# SMS_LITE_FWMGR_0_CBASS_FW_45082000h register map
Vendor: Texas Instruments
Peripheral module from a debugger description file (folder am62L).
Registers are 32-bit, read-write, reset 0x0 unless marked. A register's access mark holds for its fields unless they carry their own. Offsets are as the file gives them; lines under a group give offsets from that group; [hi:lo] are bit positions; {n}, {i} and the like mark numbered series; 'fields as' and 'values as' point back to an identical list; <NAME> marks a mode.

## cbass_fw
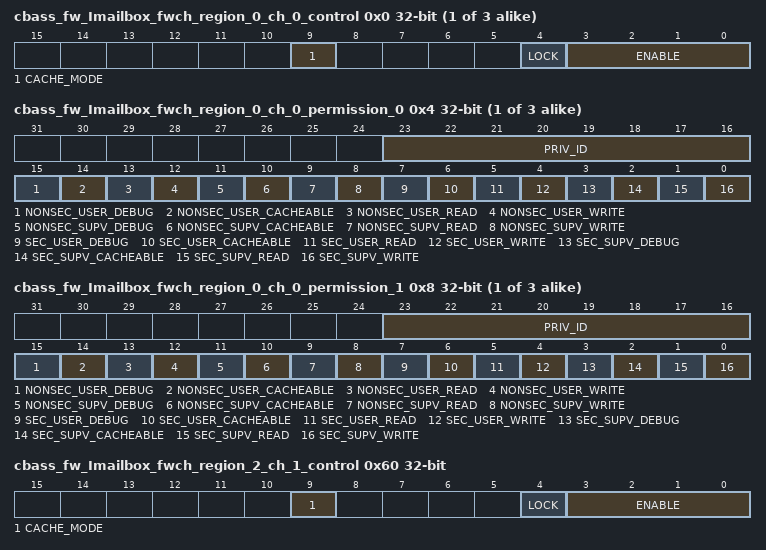
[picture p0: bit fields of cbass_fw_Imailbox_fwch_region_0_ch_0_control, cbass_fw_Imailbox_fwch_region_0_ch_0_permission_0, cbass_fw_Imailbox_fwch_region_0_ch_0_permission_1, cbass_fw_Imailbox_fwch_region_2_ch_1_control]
{0x0+0x20*i} cbass_fw_Imailbox_fwch_region_{i}_ch_0_control access not given (i=0..2) — The FW Region {i} Channel 0 Control Register defines the control fields for the slave Imailbox.cfg region {i} channel 0 firewall.
  [9] CACHE_MODE rw — Cache mode for region. Set to 1 to check cache permissions. Set to 0 to ignore cache permissions. Reset Source: sms_custom_rst_mod_g_rst_n
  [4] LOCK — Lock region. Once set region values cannot be modified. Reset Source: sms_custom_rst_mod_g_rst_n (access R/W1TS)
  [3:0] ENABLE rw — Enable region. A value of 0xA enables, others disable. Reset Source: sms_custom_rst_mod_g_rst_n
{0x4+0x20*i} cbass_fw_Imailbox_fwch_region_{i}_ch_0_permission_0 (i=0..2) — The FW Region {i} Channel 0 Permission 0 Register defines the permissions for the slave Imailbox.cfg region {i} channel 0 firewall.
  [23:16] PRIV_ID — Allowed privid. Reset Source: sms_custom_rst_mod_g_rst_n
  [15] NONSEC_USER_DEBUG — Non-secure user debug allowed. Reset Source: sms_custom_rst_mod_g_rst_n
  [14] NONSEC_USER_CACHEABLE — Non-secure user cacheable allowed. Reset Source: sms_custom_rst_mod_g_rst_n
  [13] NONSEC_USER_READ — Non-secure user read allowed. Reset Source: sms_custom_rst_mod_g_rst_n
  [12] NONSEC_USER_WRITE — Non-secure user write allowed. Reset Source: sms_custom_rst_mod_g_rst_n
  [11] NONSEC_SUPV_DEBUG — Non-secure supervisor debug allowed. Reset Source: sms_custom_rst_mod_g_rst_n
  [10] NONSEC_SUPV_CACHEABLE — Non-secure supervisor cacheable allowed. Reset Source: sms_custom_rst_mod_g_rst_n
  [9] NONSEC_SUPV_READ — Non-secure supervisor read allowed. Reset Source: sms_custom_rst_mod_g_rst_n
  [8] NONSEC_SUPV_WRITE — Non-secure supervisor write allowed. Reset Source: sms_custom_rst_mod_g_rst_n
  [7] SEC_USER_DEBUG — Secure user debug allowed. Reset Source: sms_custom_rst_mod_g_rst_n
  [6] SEC_USER_CACHEABLE — Secure user cacheable allowed. Reset Source: sms_custom_rst_mod_g_rst_n
  [5] SEC_USER_READ — Secure user read allowed. Reset Source: sms_custom_rst_mod_g_rst_n
  [4] SEC_USER_WRITE — Secure user write allowed. Reset Source: sms_custom_rst_mod_g_rst_n
  [3] SEC_SUPV_DEBUG — Secure supervisor debug allowed. Reset Source: sms_custom_rst_mod_g_rst_n
  [2] SEC_SUPV_CACHEABLE — Secure supervisor cacheable allowed. Reset Source: sms_custom_rst_mod_g_rst_n
  [1] SEC_SUPV_READ — Secure supervisor read allowed. Reset Source: sms_custom_rst_mod_g_rst_n
  [0] SEC_SUPV_WRITE — Secure supervisor write allowed. Reset Source: sms_custom_rst_mod_g_rst_n
{0x8+0x20*i} cbass_fw_Imailbox_fwch_region_{i}_ch_0_permission_1 (i=0..2) — The FW Region {i} Channel 0 Permission 1 Register defines the permissions for the slave Imailbox.cfg region {i} channel 0 firewall.
  fields as cbass_fw_Imailbox_fwch_region_0_ch_0_permission_0
0x60 cbass_fw_Imailbox_fwch_region_2_ch_1_control access not given — The FW Region 2 Channel 1 Control Register defines the control fields for the slave Imailbox.cfg region 2 channel 1 firewall.
  fields as cbass_fw_Imailbox_fwch_region_0_ch_0_control
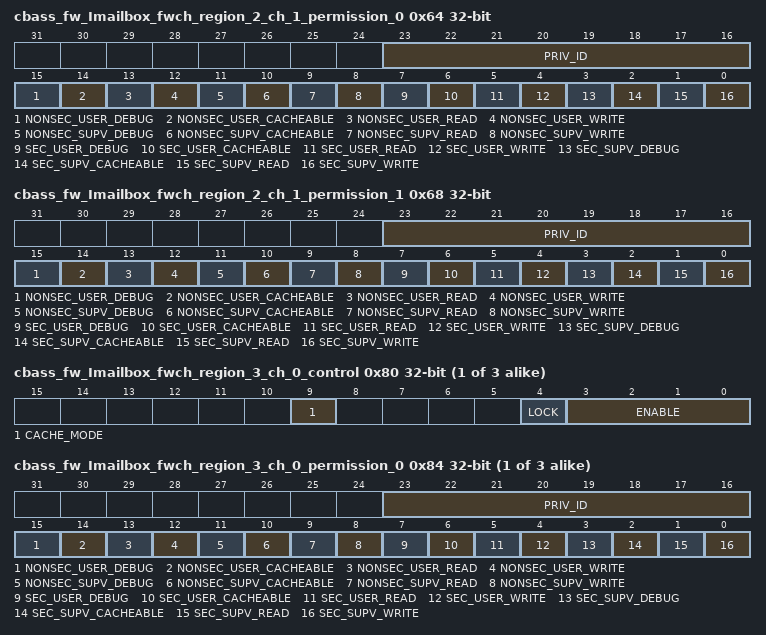
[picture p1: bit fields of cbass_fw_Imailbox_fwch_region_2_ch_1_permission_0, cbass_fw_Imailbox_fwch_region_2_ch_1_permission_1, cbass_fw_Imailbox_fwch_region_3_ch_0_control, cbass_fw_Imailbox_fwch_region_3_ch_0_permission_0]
0x64 cbass_fw_Imailbox_fwch_region_2_ch_1_permission_0 — The FW Region 2 Channel 1 Permission 0 Register defines the permissions for the slave Imailbox.cfg region 2 channel 1 firewall.
  fields as cbass_fw_Imailbox_fwch_region_0_ch_0_permission_0
0x68 cbass_fw_Imailbox_fwch_region_2_ch_1_permission_1 — The FW Region 2 Channel 1 Permission 1 Register defines the permissions for the slave Imailbox.cfg region 2 channel 1 firewall.
  fields as cbass_fw_Imailbox_fwch_region_0_ch_0_permission_0
{0x20+0x20*i} cbass_fw_Imailbox_fwch_region_{i}_ch_0_control access not given (i=3..5) — The FW Region {i} Channel 0 Control Register defines the control fields for the slave Imailbox.cfg region {i} channel 0 firewall.
  fields as cbass_fw_Imailbox_fwch_region_0_ch_0_control
{0x24+0x20*i} cbass_fw_Imailbox_fwch_region_{i}_ch_0_permission_0 (i=3..5) — The FW Region {i} Channel 0 Permission 0 Register defines the permissions for the slave Imailbox.cfg region {i} channel 0 firewall.
  fields as cbass_fw_Imailbox_fwch_region_0_ch_0_permission_0
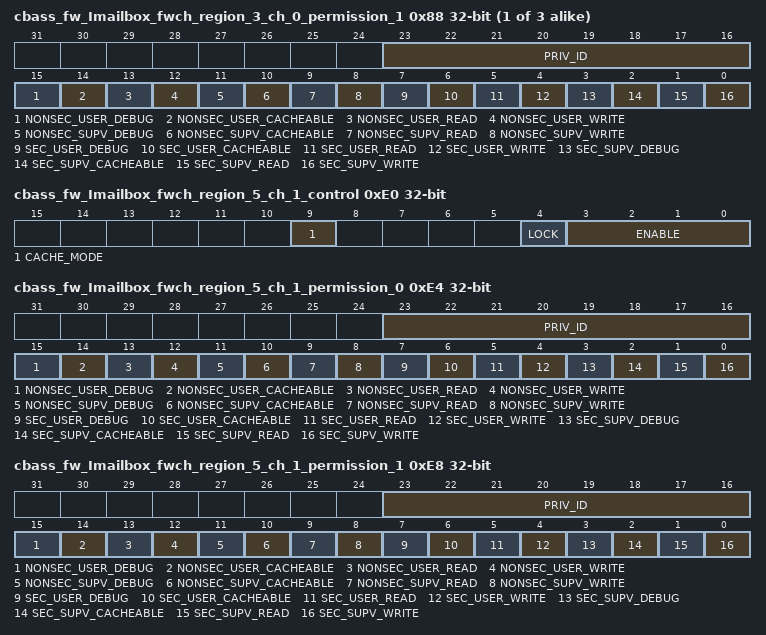
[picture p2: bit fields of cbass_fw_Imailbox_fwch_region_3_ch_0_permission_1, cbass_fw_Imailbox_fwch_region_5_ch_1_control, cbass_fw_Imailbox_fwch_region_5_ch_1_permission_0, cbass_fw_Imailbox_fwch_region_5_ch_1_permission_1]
{0x28+0x20*i} cbass_fw_Imailbox_fwch_region_{i}_ch_0_permission_1 (i=3..5) — The FW Region {i} Channel 0 Permission 1 Register defines the permissions for the slave Imailbox.cfg region {i} channel 0 firewall.
  fields as cbass_fw_Imailbox_fwch_region_0_ch_0_permission_0
0xE0 cbass_fw_Imailbox_fwch_region_5_ch_1_control access not given — The FW Region 5 Channel 1 Control Register defines the control fields for the slave Imailbox.cfg region 5 channel 1 firewall.
  fields as cbass_fw_Imailbox_fwch_region_0_ch_0_control
0xE4 cbass_fw_Imailbox_fwch_region_5_ch_1_permission_0 — The FW Region 5 Channel 1 Permission 0 Register defines the permissions for the slave Imailbox.cfg region 5 channel 1 firewall.
  fields as cbass_fw_Imailbox_fwch_region_0_ch_0_permission_0
0xE8 cbass_fw_Imailbox_fwch_region_5_ch_1_permission_1 — The FW Region 5 Channel 1 Permission 1 Register defines the permissions for the slave Imailbox.cfg region 5 channel 1 firewall.
  fields as cbass_fw_Imailbox_fwch_region_0_ch_0_permission_0
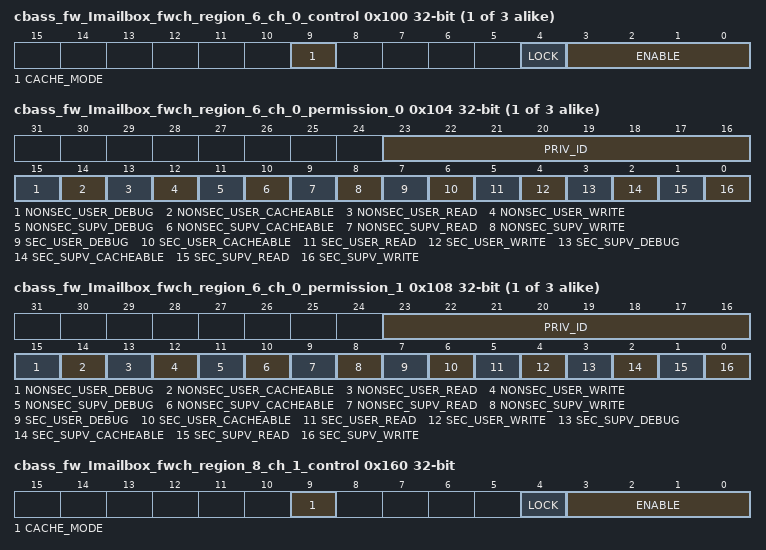
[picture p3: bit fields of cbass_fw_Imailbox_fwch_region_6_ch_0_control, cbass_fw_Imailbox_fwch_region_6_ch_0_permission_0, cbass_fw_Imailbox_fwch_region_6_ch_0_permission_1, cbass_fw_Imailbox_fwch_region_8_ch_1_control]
{0x40+0x20*i} cbass_fw_Imailbox_fwch_region_{i}_ch_0_control access not given (i=6..8) — The FW Region {i} Channel 0 Control Register defines the control fields for the slave Imailbox.cfg region {i} channel 0 firewall.
  fields as cbass_fw_Imailbox_fwch_region_0_ch_0_control
{0x44+0x20*i} cbass_fw_Imailbox_fwch_region_{i}_ch_0_permission_0 (i=6..8) — The FW Region {i} Channel 0 Permission 0 Register defines the permissions for the slave Imailbox.cfg region {i} channel 0 firewall.
  fields as cbass_fw_Imailbox_fwch_region_0_ch_0_permission_0
{0x48+0x20*i} cbass_fw_Imailbox_fwch_region_{i}_ch_0_permission_1 (i=6..8) — The FW Region {i} Channel 0 Permission 1 Register defines the permissions for the slave Imailbox.cfg region {i} channel 0 firewall.
  fields as cbass_fw_Imailbox_fwch_region_0_ch_0_permission_0
0x160 cbass_fw_Imailbox_fwch_region_8_ch_1_control access not given — The FW Region 8 Channel 1 Control Register defines the control fields for the slave Imailbox.cfg region 8 channel 1 firewall.
  fields as cbass_fw_Imailbox_fwch_region_0_ch_0_control
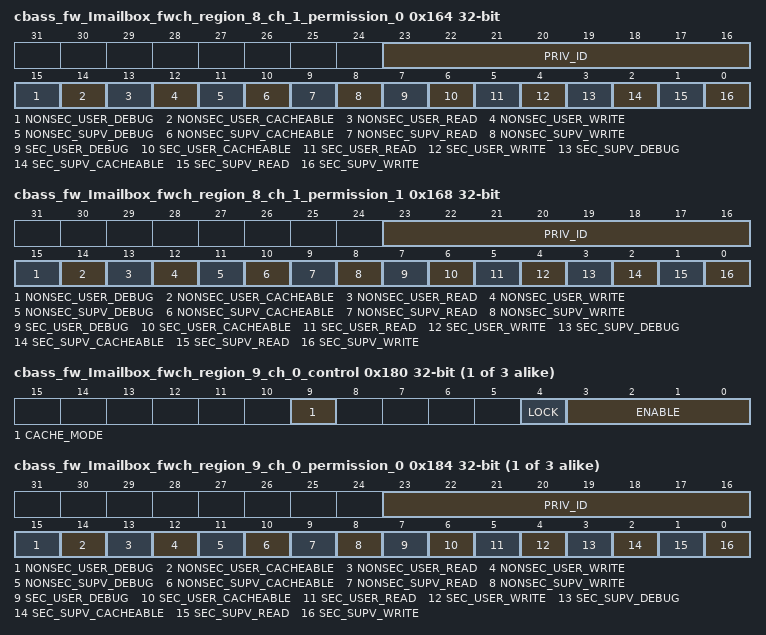
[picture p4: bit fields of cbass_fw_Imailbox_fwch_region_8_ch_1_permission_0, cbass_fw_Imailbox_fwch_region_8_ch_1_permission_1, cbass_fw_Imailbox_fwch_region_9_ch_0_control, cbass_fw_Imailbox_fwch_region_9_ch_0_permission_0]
0x164 cbass_fw_Imailbox_fwch_region_8_ch_1_permission_0 — The FW Region 8 Channel 1 Permission 0 Register defines the permissions for the slave Imailbox.cfg region 8 channel 1 firewall.
  fields as cbass_fw_Imailbox_fwch_region_0_ch_0_permission_0
0x168 cbass_fw_Imailbox_fwch_region_8_ch_1_permission_1 — The FW Region 8 Channel 1 Permission 1 Register defines the permissions for the slave Imailbox.cfg region 8 channel 1 firewall.
  fields as cbass_fw_Imailbox_fwch_region_0_ch_0_permission_0
{0x60+0x20*i} cbass_fw_Imailbox_fwch_region_{i}_ch_0_control access not given (i=9..11) — The FW Region {i} Channel 0 Control Register defines the control fields for the slave Imailbox.cfg region {i} channel 0 firewall.
  fields as cbass_fw_Imailbox_fwch_region_0_ch_0_control
{0x64+0x20*i} cbass_fw_Imailbox_fwch_region_{i}_ch_0_permission_0 (i=9..11) — The FW Region {i} Channel 0 Permission 0 Register defines the permissions for the slave Imailbox.cfg region {i} channel 0 firewall.
  fields as cbass_fw_Imailbox_fwch_region_0_ch_0_permission_0
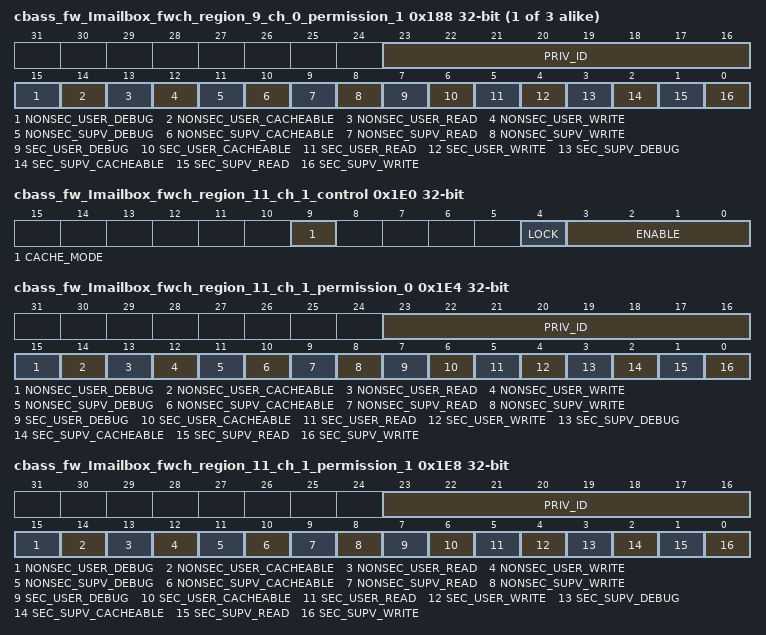
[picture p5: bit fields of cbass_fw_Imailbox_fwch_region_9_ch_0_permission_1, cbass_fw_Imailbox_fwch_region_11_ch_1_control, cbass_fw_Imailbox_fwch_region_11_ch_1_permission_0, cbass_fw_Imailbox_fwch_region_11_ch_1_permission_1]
{0x68+0x20*i} cbass_fw_Imailbox_fwch_region_{i}_ch_0_permission_1 (i=9..11) — The FW Region {i} Channel 0 Permission 1 Register defines the permissions for the slave Imailbox.cfg region {i} channel 0 firewall.
  fields as cbass_fw_Imailbox_fwch_region_0_ch_0_permission_0
0x1E0 cbass_fw_Imailbox_fwch_region_11_ch_1_control access not given — The FW Region 11 Channel 1 Control Register defines the control fields for the slave Imailbox.cfg region 11 channel 1 firewall.
  fields as cbass_fw_Imailbox_fwch_region_0_ch_0_control
0x1E4 cbass_fw_Imailbox_fwch_region_11_ch_1_permission_0 — The FW Region 11 Channel 1 Permission 0 Register defines the permissions for the slave Imailbox.cfg region 11 channel 1 firewall.
  fields as cbass_fw_Imailbox_fwch_region_0_ch_0_permission_0
0x1E8 cbass_fw_Imailbox_fwch_region_11_ch_1_permission_1 — The FW Region 11 Channel 1 Permission 1 Register defines the permissions for the slave Imailbox.cfg region 11 channel 1 firewall.
  fields as cbass_fw_Imailbox_fwch_region_0_ch_0_permission_0
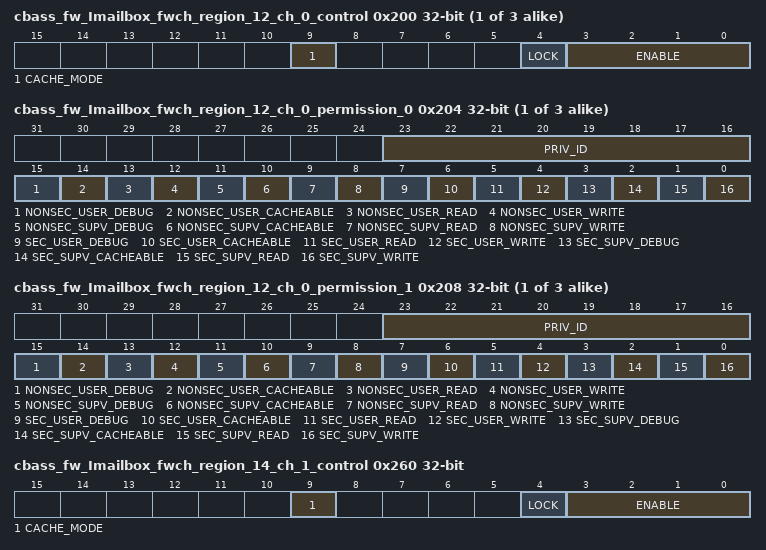
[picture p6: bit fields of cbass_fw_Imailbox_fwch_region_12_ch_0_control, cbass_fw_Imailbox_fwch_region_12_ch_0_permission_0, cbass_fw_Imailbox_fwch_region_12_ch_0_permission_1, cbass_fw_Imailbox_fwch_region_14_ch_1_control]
{0x80+0x20*i} cbass_fw_Imailbox_fwch_region_{i}_ch_0_control access not given (i=12..14) — The FW Region {i} Channel 0 Control Register defines the control fields for the slave Imailbox.cfg region {i} channel 0 firewall.
  fields as cbass_fw_Imailbox_fwch_region_0_ch_0_control
{0x84+0x20*i} cbass_fw_Imailbox_fwch_region_{i}_ch_0_permission_0 (i=12..14) — The FW Region {i} Channel 0 Permission 0 Register defines the permissions for the slave Imailbox.cfg region {i} channel 0 firewall.
  fields as cbass_fw_Imailbox_fwch_region_0_ch_0_permission_0
{0x88+0x20*i} cbass_fw_Imailbox_fwch_region_{i}_ch_0_permission_1 (i=12..14) — The FW Region {i} Channel 0 Permission 1 Register defines the permissions for the slave Imailbox.cfg region {i} channel 0 firewall.
  fields as cbass_fw_Imailbox_fwch_region_0_ch_0_permission_0
0x260 cbass_fw_Imailbox_fwch_region_14_ch_1_control access not given — The FW Region 14 Channel 1 Control Register defines the control fields for the slave Imailbox.cfg region 14 channel 1 firewall.
  fields as cbass_fw_Imailbox_fwch_region_0_ch_0_control
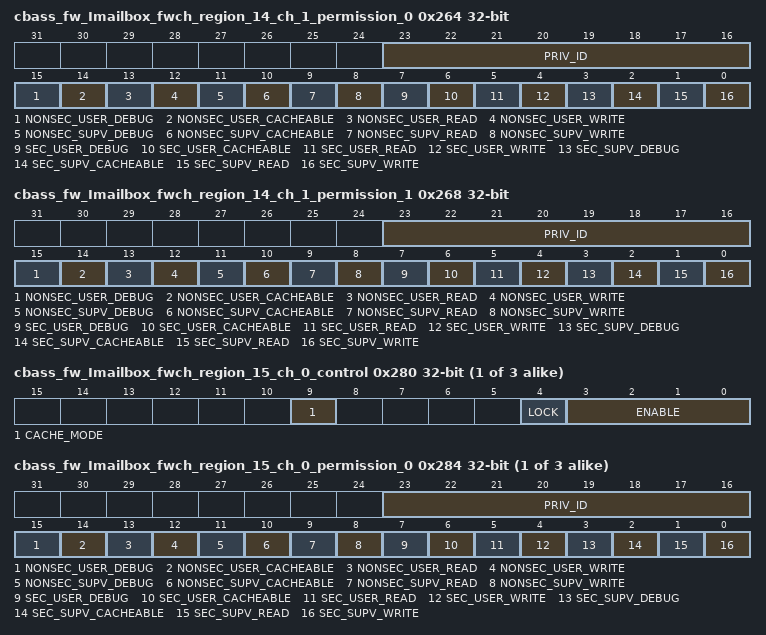
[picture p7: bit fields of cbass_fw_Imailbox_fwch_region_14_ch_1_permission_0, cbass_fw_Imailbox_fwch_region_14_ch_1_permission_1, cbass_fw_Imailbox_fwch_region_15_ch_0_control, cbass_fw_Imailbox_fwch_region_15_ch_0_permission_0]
0x264 cbass_fw_Imailbox_fwch_region_14_ch_1_permission_0 — The FW Region 14 Channel 1 Permission 0 Register defines the permissions for the slave Imailbox.cfg region 14 channel 1 firewall.
  fields as cbass_fw_Imailbox_fwch_region_0_ch_0_permission_0
0x268 cbass_fw_Imailbox_fwch_region_14_ch_1_permission_1 — The FW Region 14 Channel 1 Permission 1 Register defines the permissions for the slave Imailbox.cfg region 14 channel 1 firewall.
  fields as cbass_fw_Imailbox_fwch_region_0_ch_0_permission_0
{0xA0+0x20*i} cbass_fw_Imailbox_fwch_region_{i}_ch_0_control access not given (i=15..17) — The FW Region {i} Channel 0 Control Register defines the control fields for the slave Imailbox.cfg region {i} channel 0 firewall.
  fields as cbass_fw_Imailbox_fwch_region_0_ch_0_control
{0xA4+0x20*i} cbass_fw_Imailbox_fwch_region_{i}_ch_0_permission_0 (i=15..17) — The FW Region {i} Channel 0 Permission 0 Register defines the permissions for the slave Imailbox.cfg region {i} channel 0 firewall.
  fields as cbass_fw_Imailbox_fwch_region_0_ch_0_permission_0
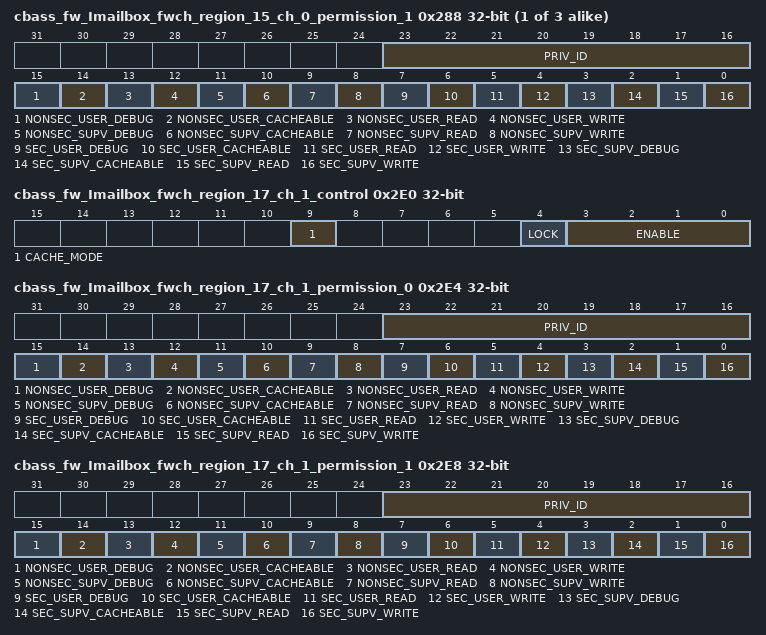
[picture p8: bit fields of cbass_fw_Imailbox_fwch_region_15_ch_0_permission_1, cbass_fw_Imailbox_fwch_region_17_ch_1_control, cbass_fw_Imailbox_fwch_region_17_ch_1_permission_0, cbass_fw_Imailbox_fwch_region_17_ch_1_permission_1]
{0xA8+0x20*i} cbass_fw_Imailbox_fwch_region_{i}_ch_0_permission_1 (i=15..17) — The FW Region {i} Channel 0 Permission 1 Register defines the permissions for the slave Imailbox.cfg region {i} channel 0 firewall.
  fields as cbass_fw_Imailbox_fwch_region_0_ch_0_permission_0
0x2E0 cbass_fw_Imailbox_fwch_region_17_ch_1_control access not given — The FW Region 17 Channel 1 Control Register defines the control fields for the slave Imailbox.cfg region 17 channel 1 firewall.
  fields as cbass_fw_Imailbox_fwch_region_0_ch_0_control
0x2E4 cbass_fw_Imailbox_fwch_region_17_ch_1_permission_0 — The FW Region 17 Channel 1 Permission 0 Register defines the permissions for the slave Imailbox.cfg region 17 channel 1 firewall.
  fields as cbass_fw_Imailbox_fwch_region_0_ch_0_permission_0
0x2E8 cbass_fw_Imailbox_fwch_region_17_ch_1_permission_1 — The FW Region 17 Channel 1 Permission 1 Register defines the permissions for the slave Imailbox.cfg region 17 channel 1 firewall.
  fields as cbass_fw_Imailbox_fwch_region_0_ch_0_permission_0
